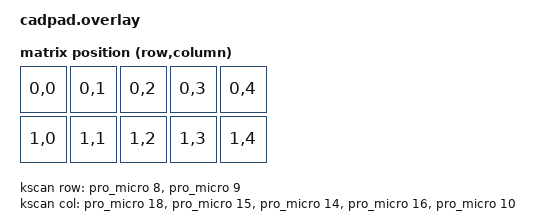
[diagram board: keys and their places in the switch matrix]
// This file was generated from a template. Edit it to match your keyboard.
// See https://zmk.dev/docs/development/hardware-integration/new-shield for more
// instructions.

#include <dt-bindings/zmk/matrix_transform.h>

#include "cadpad-layouts.dtsi"

/ {
    chosen {
        zmk,physical-layout = &default_layout;
    };

    kscan: kscan {
        // If the hardware does not use a switch matrix, change this to the
        // appropriate driver and update the properties below to match.
        // See https://zmk.dev/docs/config/kscan for supported key scan drivers.
        compatible = "zmk,kscan-gpio-matrix";
        // Set this to "col2row" or "row2col" to match the hardware. If using
        // "row2col", change the col-gpios to (GPIO_ACTIVE_HIGH | GPIO_PULL_DOWN)
        // and the row-gpios to GPIO_ACTIVE_HIGH.
        diode-direction = "col2row";
        wakeup-source;

        // Replace these comments with the GPIO pins in the matrix.
        // See https://zmk.dev/docs/development/hardware-integration/new-shield#shield-overlays
        col-gpios
            = <&pro_micro 18 GPIO_ACTIVE_HIGH>
            , <&pro_micro 15 GPIO_ACTIVE_HIGH>
            , <&pro_micro 14 GPIO_ACTIVE_HIGH>
            , <&pro_micro 16 GPIO_ACTIVE_HIGH>
            , <&pro_micro 10 GPIO_ACTIVE_HIGH>
            ;

        row-gpios
            = <&pro_micro 8 (GPIO_ACTIVE_HIGH | GPIO_PULL_DOWN)>
            , <&pro_micro 9 (GPIO_ACTIVE_HIGH | GPIO_PULL_DOWN)>
            ;
    };

    default_transform: default_transform {
        // See https://zmk.dev/docs/development/hardware-integration/new-shield#matrix-transform
        // for how to configure this
        compatible = "zmk,matrix-transform";
        columns = <5>;
        rows = <2>;

        map = <
            RC(0, 0) RC(0, 1) RC(0, 2) RC(0, 3) RC(0, 4)
            RC(1, 0) RC(1, 1) RC(1, 2) RC(1, 3) RC(1, 4)
        >;
    };
};
